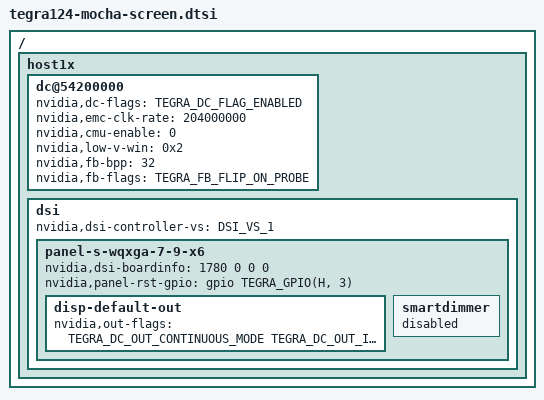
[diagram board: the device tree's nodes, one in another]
/*
 * arch/arm/boot/dts/tegra124-platforms/mocha/tegra124-mocha-screen.dtsi
 *
 * Copyright (c) 2018, Smoke team. All rights reserved.
 *
 * This program is free software; you can redistribute it and/or modify it
 * under the terms and conditions of the GNU General Public License,
 * version 2, as published by the Free Software Foundation.
 *
 * This program is distributed in the hope it will be useful, but WITHOUT
 * ANY WARRANTY; without even the implied warranty of MERCHANTABILITY or
 * FITNESS FOR A PARTICULAR PURPOSE.  See the GNU General Public License for
 * more details.
 *
 */

#include "../../panel-s-wqxga-7-9-x6.dtsi"
#include "tegra124-mocha-synaptics-touchscreen.dtsi"
#include "tegra124-mocha-leds.dtsi"
#include "tegra124-mocha-backlight.dtsi"

/ {
	host1x {
		/* tegradc.0 */
		dc@54200000 {
			status = "okay";
			nvidia,dc-flags = <TEGRA_DC_FLAG_ENABLED>;
			nvidia,emc-clk-rate = <204000000>;
			nvidia,cmu-enable = <0>;
			nvidia,low-v-win = <0x2>;
			nvidia,fb-bpp = <32>; /* bits per pixel */
			nvidia,fb-flags = <TEGRA_FB_FLIP_ON_PROBE>;
		};
		dsi {
			nvidia,dsi-controller-vs = <DSI_VS_1>;
			status = "okay";
			panel-s-wqxga-7-9-x6 {
				nvidia,dsi-boardinfo = <1780 0 0 0>;
				nvidia,panel-rst-gpio = <&gpio TEGRA_GPIO(H, 3) 0>; /* PH3 */	
				disp-default-out {
					nvidia,out-flags = <TEGRA_DC_OUT_CONTINUOUS_MODE TEGRA_DC_OUT_INITIALIZED_MODE>;
				};	
				smartdimmer {
						status = "disabled";
				};
			};
		};
	};
};
